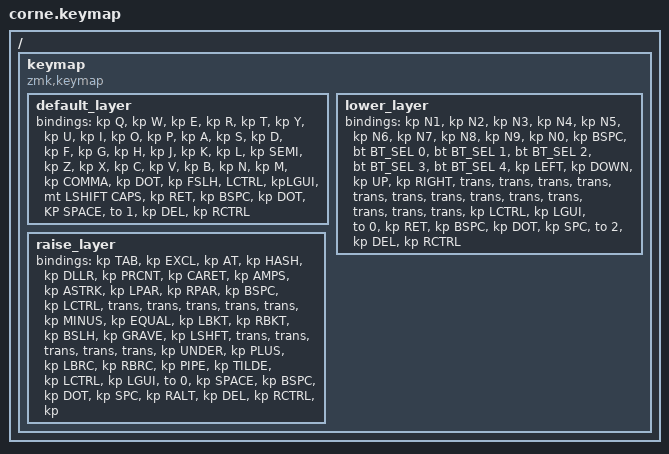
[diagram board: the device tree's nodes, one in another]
/*
 * Copyright (c) 2020 The ZMK Contributors
 *
 * SPDX-License-Identifier: MIT
 */

#include <behaviors.dtsi>
#include <dt-bindings/zmk/keys.h>
#include <dt-bindings/zmk/bt.h>

/ {
        keymap {
                compatible = "zmk,keymap";

                default_layer {
// -----------------------------------------------------------------------------------------
// |  Q  |  W  |  E  |  R  |  T  |   |  Y  |  U   |  I  |  O  |  P  |
// |  A  |  S  |  D  |  F  |  G  |   |  H  |  J   |  K  |  L  |  ;  |
// |  Z  |  X  |  C  |  V  |  B  |   |  N  |  M   |  ,  |  .  |  /  |
// |     |     |SHIFT| ENT |BSPC |   |  .  | SPC  | LY1 | ALT | CTL |
                        bindings = <
   &kp Q &kp W &kp E &kp R &kp T   &kp Y &kp U  &kp I     &kp O   &kp P   
   &kp A &kp S &kp D &kp F &kp G   &kp H &kp J  &kp K     &kp L   &kp SEMI
   &kp Z &kp X &kp C &kp V &kp B   &kp N &kp M  &kp COMMA &kp DOT &kp FSLH
   &LCTRL  &kpLGUI &mt LSHIFT CAPS &kp RET &kp BSPC     &kp DOT &KP SPACE &to 1 &kp DEL &kp RCTRL
                        >;
                };
                lower_layer {
// -----------------------------------------------------------------------------------------
// |  1  |  2  |  3  |  4  |  5  |   |  6  |  7  |  8  |  9  |  0  |
// | BT1 | BT2 | BT3 | BT4 | BT5 |   | LFT | DWN |  UP | RGT |     |
// |     |     |     |     |     |   |     |     |     |     |     |
// |     |LGUI | LY0 |     | SPC |   | ENT |     | ALT |     |     | 
                        bindings = <
   &kp N1       &kp N2       &kp N3       &kp N4       &kp N5         &kp N6   &kp N7   &kp N8 &kp N9    &kp N0 &kp BSPC
   &bt BT_SEL 0 &bt BT_SEL 1 &bt BT_SEL 2 &bt BT_SEL 3 &bt BT_SEL 4   &kp LEFT &kp DOWN &kp UP &kp RIGHT &trans &trans
   &trans       &trans       &trans       &trans       &trans         &trans   &trans   &trans &trans    &trans &trans
   &kp LCTRL    &kp LGUI     &to 0        &kp RET      &kp BSPC       &kp DOT  &kp SPC  &to 2  &kp DEL   &kp RCTRL
                        >;
                };

                raise_layer {
// -----------------------------------------------------------------------------------------
// |  TAB |  !  |  @  |  #  |  $  |  %  |   |  ^  |  &  |  *  |  (  |  )  | BSPC |
// | CTRL |     |     |     |     |     |   |  -  |  =  |  [  |  ]  |  \  |  `   |
// | SHFT |     |     |     |     |     |   |  _  |  +  |  {  |  }  | "|" |  ~   |
// |      |     |     | GUI |     | SPC |   | ENT |     | ALT |     |     |      |
                        bindings = <
   &kp  TAB  &kp EXCL &kp AT &kp HASH &kp DLLR &kp PRCNT   &kp CARET &kp AMPS  &kp ASTRK &kp LPAR &kp RPAR &kp BSPC
   &kp LCTRL &trans   &trans &trans   &trans   &trans      &kp MINUS &kp EQUAL &kp LBKT  &kp RBKT &kp BSLH &kp GRAVE
   &kp LSHFT &trans   &trans &trans   &trans   &trans      &kp UNDER &kp PLUS  &kp LBRC  &kp RBRC &kp PIPE &kp TILDE
   &kp LCTRL &kp LGUI &to 0  &kp SPACE &kp BSPC &kp DOT    &kp SPC   &kp RALT  &kp DEL   &kp RCTRL &kp 
                        >;
                };
        };
};
